# VPAC0_LDC0_ECC_AGGR_0_IVPAC_TOP_0_CFG_SLV_PAR_VPAC_LDC0_S_VBUSP_KSDW_ECC_AGGR_CFG register map
Vendor: Texas Instruments
Peripheral module from a debugger description file (folder am62A).
Registers are 32-bit, access not given, reset 0x0 unless marked. A register's access mark holds for its fields unless they carry their own. Offsets are as the file gives them; lines under a group give offsets from that group; [hi:lo] are bit positions; {n}, {i} and the like mark numbered series; 'fields as' and 'values as' point back to an identical list; <NAME> marks a mode.

## VPAC0_LDC0_ECC_AGGR_0_IVPAC_TOP_0_CFG_SLV_PAR_VPAC_LDC0_S_VBUSP_KSDW_ECC_AGGR_CFG
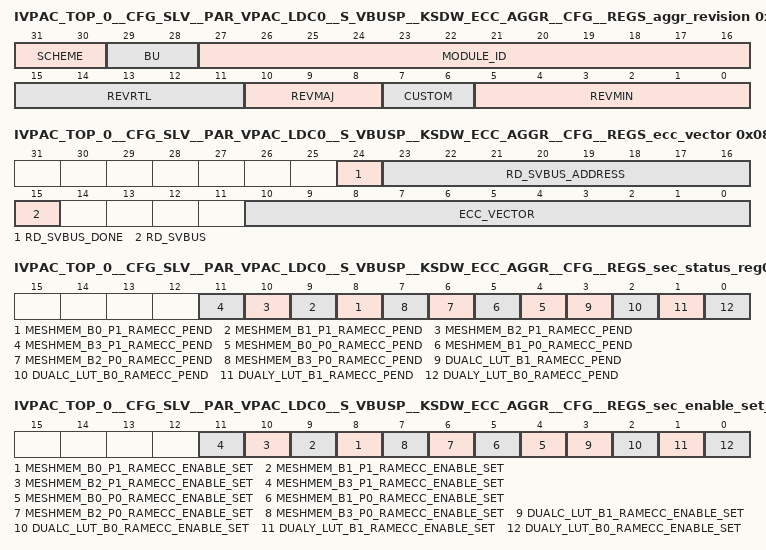
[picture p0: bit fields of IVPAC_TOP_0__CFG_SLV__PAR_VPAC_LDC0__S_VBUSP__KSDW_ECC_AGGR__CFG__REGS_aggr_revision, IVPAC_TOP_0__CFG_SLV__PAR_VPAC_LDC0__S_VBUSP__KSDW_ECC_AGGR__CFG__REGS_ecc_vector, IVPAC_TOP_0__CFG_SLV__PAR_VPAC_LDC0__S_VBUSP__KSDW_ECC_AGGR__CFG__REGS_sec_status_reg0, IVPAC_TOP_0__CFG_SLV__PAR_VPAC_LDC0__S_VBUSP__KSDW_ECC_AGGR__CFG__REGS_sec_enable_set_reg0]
0x00 IVPAC_TOP_0__CFG_SLV__PAR_VPAC_LDC0__S_VBUSP__KSDW_ECC_AGGR__CFG__REGS_aggr_revision ro reset 0x66A03A01 — Revision parameters
  [31:30] SCHEME
  [29:28] BU
  [27:16] MODULE_ID
  [15:11] REVRTL — RTL version
  [10:8] REVMAJ — Major version
  [7:6] CUSTOM — Custom version
  [5:0] REVMIN — Minor version
0x08 IVPAC_TOP_0__CFG_SLV__PAR_VPAC_LDC0__S_VBUSP__KSDW_ECC_AGGR__CFG__REGS_ecc_vector — ECC Vector Register
  [24] RD_SVBUS_DONE — Status to indicate if read on serial VBUS is complete, write of any value will clear this bit. (access R/W1TC)
  [23:16] RD_SVBUS_ADDRESS rw — Read address
  [15] RD_SVBUS — Write 1 to trigger a read on the serial VBUS (access R/W1TS)
  [10:0] ECC_VECTOR rw — Value written to select the corresponding ECC RAM for control or status
0x0C IVPAC_TOP_0__CFG_SLV__PAR_VPAC_LDC0__S_VBUSP__KSDW_ECC_AGGR__CFG__REGS_misc_status ro reset 0xC — Misc Status
  [10:0] NUM_RAMS — Indicates the number of RAMS serviced by the ECC aggregator
0x10 IVPAC_TOP_0__CFG_SLV__PAR_VPAC_LDC0__S_VBUSP__KSDW_ECC_AGGR__CFG__REGS_reserved_svbus rw — Reference other documents that contain the ECC RAM wrapper and EDC controller serial vbus register sets.
  [31:0] DATA — Serial VBUS register data
0x3C IVPAC_TOP_0__CFG_SLV__PAR_VPAC_LDC0__S_VBUSP__KSDW_ECC_AGGR__CFG__REGS_sec_eoi_reg — EOI Register
  [0] EOI_WR — EOI Register (access R/W1TS)
0x40 IVPAC_TOP_0__CFG_SLV__PAR_VPAC_LDC0__S_VBUSP__KSDW_ECC_AGGR__CFG__REGS_sec_status_reg0 — Interrupt Status Register 0
  [n+8] MESHMEM_B{n}_P1_RAMECC_PEND (n=0..3) — Interrupt Pending Status for meshmem_b{n}_p1_ramecc_pend (access R/W1TS)
  [n+4] MESHMEM_B{n}_P0_RAMECC_PEND (n=0..3) — Interrupt Pending Status for meshmem_b{n}_p0_ramecc_pend (access R/W1TS)
  [3] DUALC_LUT_B1_RAMECC_PEND — Interrupt Pending Status for dualc_lut_b1_ramecc_pend (access R/W1TS)
  [2] DUALC_LUT_B0_RAMECC_PEND — Interrupt Pending Status for dualc_lut_b0_ramecc_pend (access R/W1TS)
  [1] DUALY_LUT_B1_RAMECC_PEND — Interrupt Pending Status for dualy_lut_b1_ramecc_pend (access R/W1TS)
  [0] DUALY_LUT_B0_RAMECC_PEND — Interrupt Pending Status for dualy_lut_b0_ramecc_pend (access R/W1TS)
0x80 IVPAC_TOP_0__CFG_SLV__PAR_VPAC_LDC0__S_VBUSP__KSDW_ECC_AGGR__CFG__REGS_sec_enable_set_reg0 — Interrupt Enable Set Register 0
  [n+8] MESHMEM_B{n}_P1_RAMECC_ENABLE_SET (n=0..3) — Interrupt Enable Set Register for meshmem_b{n}_p1_ramecc_pend (access R/W1TS)
  [n+4] MESHMEM_B{n}_P0_RAMECC_ENABLE_SET (n=0..3) — Interrupt Enable Set Register for meshmem_b{n}_p0_ramecc_pend (access R/W1TS)
  [3] DUALC_LUT_B1_RAMECC_ENABLE_SET — Interrupt Enable Set Register for dualc_lut_b1_ramecc_pend (access R/W1TS)
  [2] DUALC_LUT_B0_RAMECC_ENABLE_SET — Interrupt Enable Set Register for dualc_lut_b0_ramecc_pend (access R/W1TS)
  [1] DUALY_LUT_B1_RAMECC_ENABLE_SET — Interrupt Enable Set Register for dualy_lut_b1_ramecc_pend (access R/W1TS)
  [0] DUALY_LUT_B0_RAMECC_ENABLE_SET — Interrupt Enable Set Register for dualy_lut_b0_ramecc_pend (access R/W1TS)
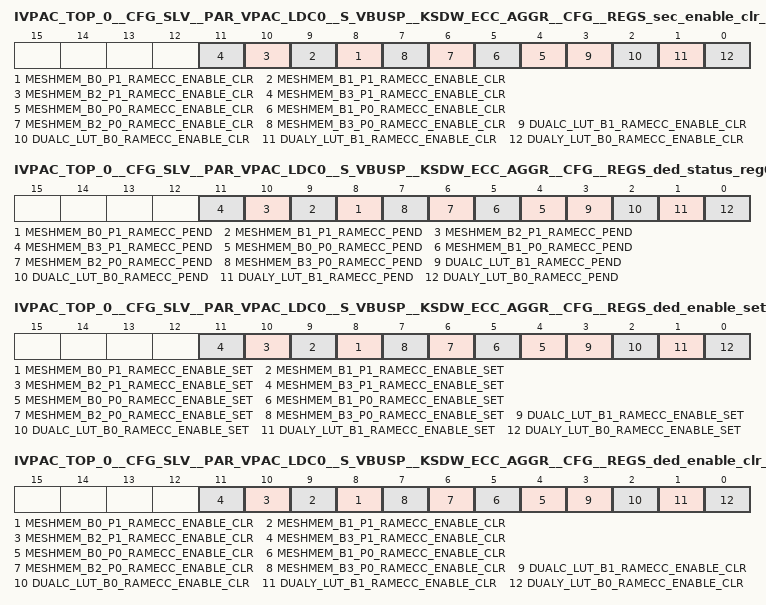
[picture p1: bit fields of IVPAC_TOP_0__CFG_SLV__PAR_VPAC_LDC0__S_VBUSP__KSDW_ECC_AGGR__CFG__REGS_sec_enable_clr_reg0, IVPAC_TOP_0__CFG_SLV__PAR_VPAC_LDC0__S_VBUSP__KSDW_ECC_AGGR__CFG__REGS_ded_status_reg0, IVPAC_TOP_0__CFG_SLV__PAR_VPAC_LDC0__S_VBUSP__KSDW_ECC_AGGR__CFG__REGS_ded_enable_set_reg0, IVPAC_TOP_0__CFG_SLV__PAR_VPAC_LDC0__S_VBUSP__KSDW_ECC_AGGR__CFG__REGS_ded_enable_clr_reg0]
0xC0 IVPAC_TOP_0__CFG_SLV__PAR_VPAC_LDC0__S_VBUSP__KSDW_ECC_AGGR__CFG__REGS_sec_enable_clr_reg0 — Interrupt Enable Clear Register 0
  [n+8] MESHMEM_B{n}_P1_RAMECC_ENABLE_CLR (n=0..3) — Interrupt Enable Clear Register for meshmem_b{n}_p1_ramecc_pend (access R/W1TC)
  [n+4] MESHMEM_B{n}_P0_RAMECC_ENABLE_CLR (n=0..3) — Interrupt Enable Clear Register for meshmem_b{n}_p0_ramecc_pend (access R/W1TC)
  [3] DUALC_LUT_B1_RAMECC_ENABLE_CLR — Interrupt Enable Clear Register for dualc_lut_b1_ramecc_pend (access R/W1TC)
  [2] DUALC_LUT_B0_RAMECC_ENABLE_CLR — Interrupt Enable Clear Register for dualc_lut_b0_ramecc_pend (access R/W1TC)
  [1] DUALY_LUT_B1_RAMECC_ENABLE_CLR — Interrupt Enable Clear Register for dualy_lut_b1_ramecc_pend (access R/W1TC)
  [0] DUALY_LUT_B0_RAMECC_ENABLE_CLR — Interrupt Enable Clear Register for dualy_lut_b0_ramecc_pend (access R/W1TC)
0x13C IVPAC_TOP_0__CFG_SLV__PAR_VPAC_LDC0__S_VBUSP__KSDW_ECC_AGGR__CFG__REGS_ded_eoi_reg — EOI Register
  [0] EOI_WR — EOI Register (access R/W1TS)
0x140 IVPAC_TOP_0__CFG_SLV__PAR_VPAC_LDC0__S_VBUSP__KSDW_ECC_AGGR__CFG__REGS_ded_status_reg0 — Interrupt Status Register 0
  fields as IVPAC_TOP_0__CFG_SLV__PAR_VPAC_LDC0__S_VBUSP__KSDW_ECC_AGGR__CFG__REGS_sec_status_reg0
0x180 IVPAC_TOP_0__CFG_SLV__PAR_VPAC_LDC0__S_VBUSP__KSDW_ECC_AGGR__CFG__REGS_ded_enable_set_reg0 — Interrupt Enable Set Register 0
  fields as IVPAC_TOP_0__CFG_SLV__PAR_VPAC_LDC0__S_VBUSP__KSDW_ECC_AGGR__CFG__REGS_sec_enable_set_reg0
0x1C0 IVPAC_TOP_0__CFG_SLV__PAR_VPAC_LDC0__S_VBUSP__KSDW_ECC_AGGR__CFG__REGS_ded_enable_clr_reg0 — Interrupt Enable Clear Register 0
  fields as IVPAC_TOP_0__CFG_SLV__PAR_VPAC_LDC0__S_VBUSP__KSDW_ECC_AGGR__CFG__REGS_sec_enable_clr_reg0
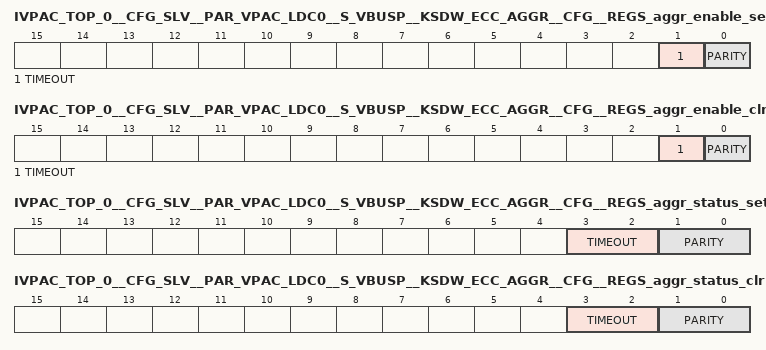
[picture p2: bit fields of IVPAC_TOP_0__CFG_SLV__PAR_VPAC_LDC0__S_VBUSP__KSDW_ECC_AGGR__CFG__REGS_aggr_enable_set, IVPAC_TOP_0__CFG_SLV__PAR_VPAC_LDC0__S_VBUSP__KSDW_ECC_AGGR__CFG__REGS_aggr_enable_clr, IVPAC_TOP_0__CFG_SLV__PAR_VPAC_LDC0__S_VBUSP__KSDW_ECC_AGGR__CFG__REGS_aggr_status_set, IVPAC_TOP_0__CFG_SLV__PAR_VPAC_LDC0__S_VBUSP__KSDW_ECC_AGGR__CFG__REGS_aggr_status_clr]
0x200 IVPAC_TOP_0__CFG_SLV__PAR_VPAC_LDC0__S_VBUSP__KSDW_ECC_AGGR__CFG__REGS_aggr_enable_set — AGGR interrupt enable set Register
  [1] TIMEOUT — interrupt enable set for svbus timeout errors (access R/W1TS)
  [0] PARITY — interrupt enable set for parity errors (access R/W1TS)
0x204 IVPAC_TOP_0__CFG_SLV__PAR_VPAC_LDC0__S_VBUSP__KSDW_ECC_AGGR__CFG__REGS_aggr_enable_clr — AGGR interrupt enable clear Register
  [1] TIMEOUT — interrupt enable clear for svbus timeout errors (access R/W1TC)
  [0] PARITY — interrupt enable clear for parity errors (access R/W1TC)
0x208 IVPAC_TOP_0__CFG_SLV__PAR_VPAC_LDC0__S_VBUSP__KSDW_ECC_AGGR__CFG__REGS_aggr_status_set — AGGR interrupt status set Register
  [3:2] TIMEOUT — interrupt status set for svbus timeout errors (access R/WI)
  [1:0] PARITY — interrupt status set for parity errors (access R/WI)
0x20C IVPAC_TOP_0__CFG_SLV__PAR_VPAC_LDC0__S_VBUSP__KSDW_ECC_AGGR__CFG__REGS_aggr_status_clr — AGGR interrupt status clear Register
  [3:2] TIMEOUT — interrupt status clear for svbus timeout errors (access R/WD)
  [1:0] PARITY — interrupt status clear for parity errors (access R/WD)
